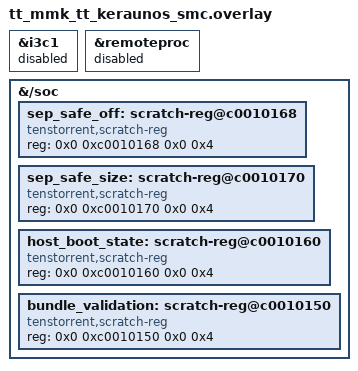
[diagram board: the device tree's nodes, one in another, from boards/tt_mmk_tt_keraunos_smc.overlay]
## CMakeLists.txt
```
# SPDX-License-Identifier: Apache-2.0

cmake_minimum_required(VERSION 3.20.0)
find_package(Zephyr REQUIRED HINTS $ENV{ZEPHYR_BASE})
project(hello_pcie)

target_sources(app PRIVATE src/main.c)
```

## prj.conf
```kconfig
# Copyright (c) 2026 Tenstorrent AI ULC
# SPDX-License-Identifier: Apache-2.0

CONFIG_PRINTK=y
CONFIG_LOG=y
CONFIG_TT_GRENDEL_PCIE=y
CONFIG_TT_GRENDEL_PCIE_HW_INIT=y
CONFIG_TT_GRENDEL_HSIO=y
```

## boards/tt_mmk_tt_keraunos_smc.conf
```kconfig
# Copyright (c) 2026 Tenstorrent AI ULC
# SPDX-License-Identifier: Apache-2.0

CONFIG_PRINTK=y

# Shell timeouts assume 1 MHz mtime; emul ticks at ~100 kHz.
CONFIG_SHELL=n
```

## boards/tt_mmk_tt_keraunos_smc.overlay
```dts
/*
 * Copyright (c) 2026 Tenstorrent AI ULC
 *
 * SPDX-License-Identifier: Apache-2.0
 */

/*
 * Emul mtime is ~100 kHz vs CONFIG_SYS_CLOCK_HW_CYCLES_PER_SEC=1 MHz, so
 * cdns_i3c_bus_init()'s k_busy_wait(201) plus DAA/CCC timeouts miss a 10 ms
 * sim-time budget. This app does not use I3C.
 */
&i3c1 {
	status = "disabled";
};

&remoteproc {
	status = "disabled";
};

&{/soc} {
	sep_safe_off: scratch-reg@c0010168 {
		/* SCRATCH[13], SEP-safe SRAM offset in [13:0] */
		compatible = "tenstorrent,scratch-reg";
		reg = <0x0 0xc0010168 0x0 0x4>;
	};

	sep_safe_size: scratch-reg@c0010170 {
		/* SCRATCH[14], SEP-safe SRAM size */
		compatible = "tenstorrent,scratch-reg";
		reg = <0x0 0xc0010170 0x0 0x4>;
	};

	host_boot_state: scratch-reg@c0010160 {
		/* SCRATCH[12] */
		compatible = "tenstorrent,scratch-reg";
		reg = <0x0 0xc0010160 0x0 0x4>;
		status = "okay";
	};

	bundle_validation: scratch-reg@c0010150 {
		/* SCRATCH[10] */
		compatible = "tenstorrent,scratch-reg";
		reg = <0x0 0xc0010150 0x0 0x4>;
		status = "okay";
	};
};
```

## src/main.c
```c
/*
 * Copyright (c) 2026 Tenstorrent AI ULC
 *
 * SPDX-License-Identifier: Apache-2.0
 */

#include <zephyr/device.h>
#include <zephyr/sys/printk.h>

#include <soc.h>

int main(void)
{
	const struct device *pcie_dev = DEVICE_DT_GET(DT_NODELABEL(pcie0));

	printk("hello_pcie on %s\n", CONFIG_BOARD_TARGET);

	if (!device_is_ready(pcie_dev)) {
		printk("pcie0 not ready\n");
		return 1;
	}

	printk("pcie0 ready\n");
	test_pass();

	/* Keep the endpoint alive; do not sleep (emul mtime is ~10x slow). */
	while (1) {
	}

	return 0;
}
```
